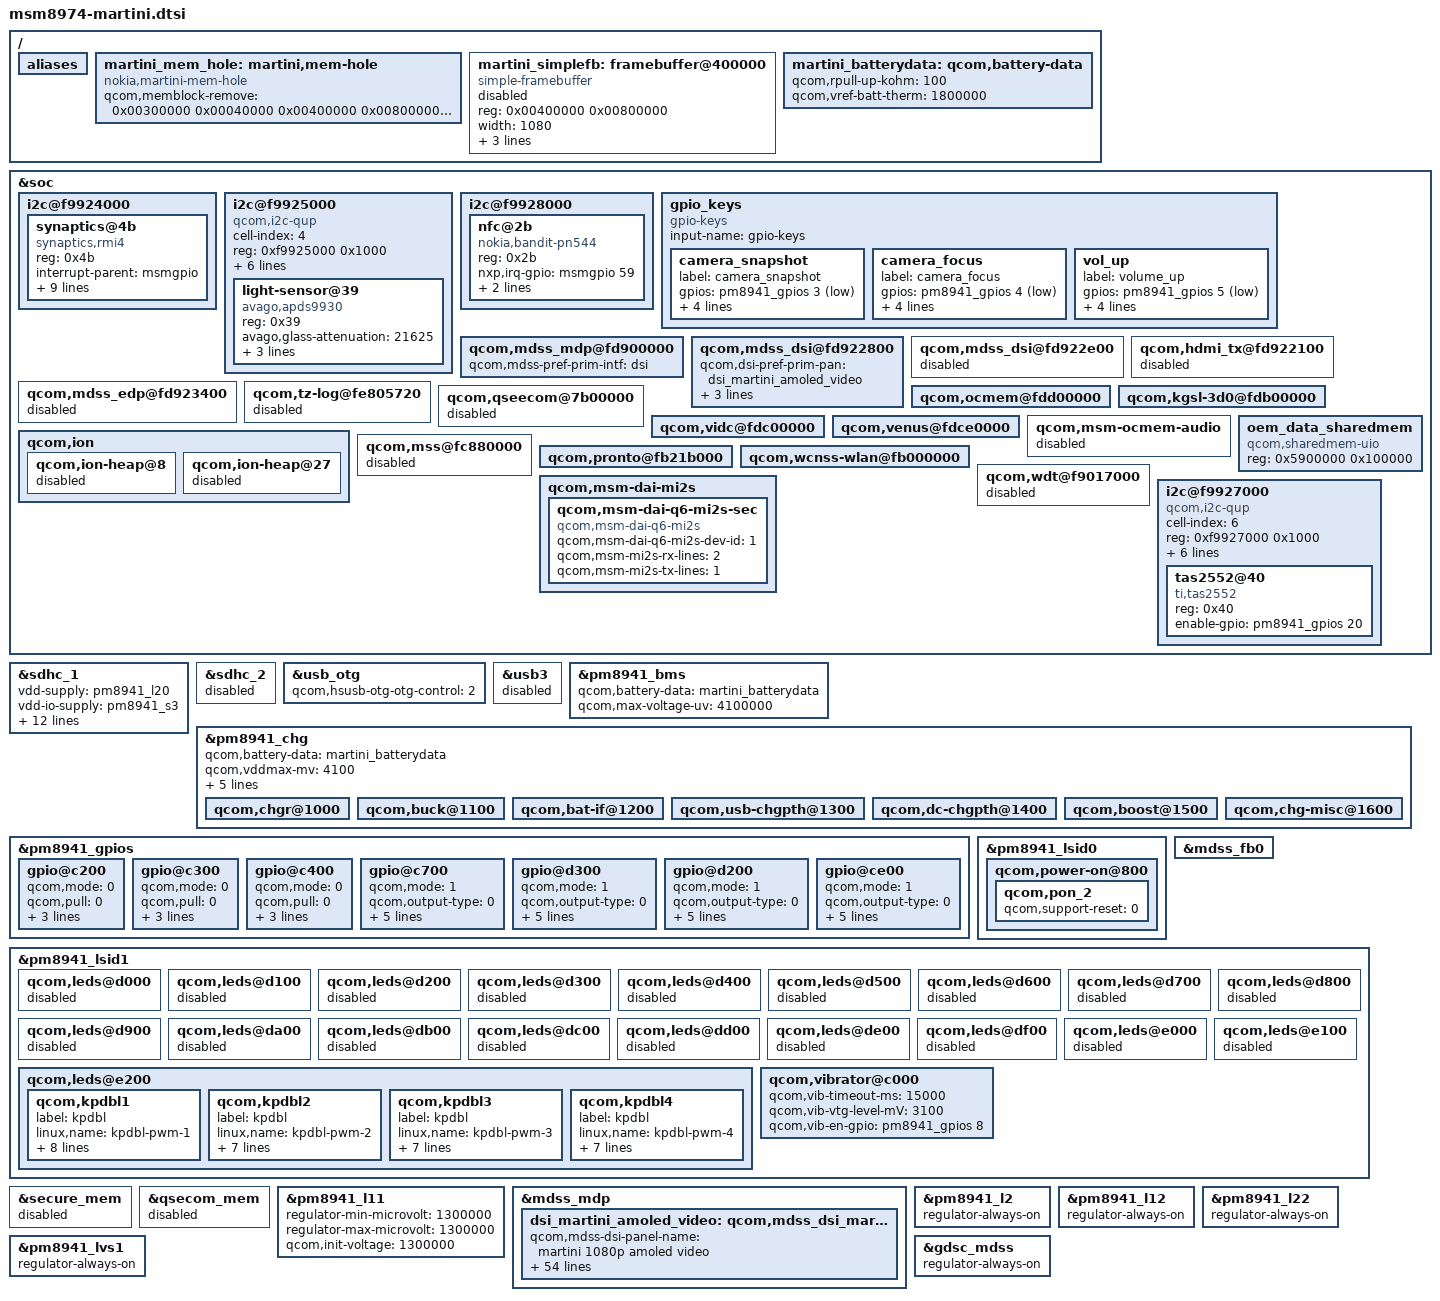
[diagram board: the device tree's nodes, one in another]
/*
 * Nokia Lumia 930 (martini), board description for the Android 3.4 kernel.
 *
 * Copyright (c) 2013, The Linux Foundation. All rights reserved.
 * Copyright (c) 2026, Lorenzo Giannoccaro.
 *
 * This program is free software; you can redistribute it and/or modify
 * it under the terms of the GNU General Public License version 2 and
 * only version 2 as published by the Free Software Foundation.
 *
 * Started from the Lumia 1520 (bandit) board, which shares the SoC, the
 * PMICs and the Windows Phone firmware. Board wiring comes from:
 *  - the stock DSDT/SSDT of the 930 as read by the mainline bring-up
 *    (Markynose, lumia930-linux): touch, light sensor, keys, UEFI parking
 *    mailboxes, framebuffer;
 *  - the LineageOS 17.1 Lumia 930 kernel (2314372037,
 *    android_kernel_nokia_martini), which boots on the phone: panel,
 *    loudspeaker amplifier, vibrator enable, WCN3680 supply, memory map,
 *    battery profile.
 * Blocks marked "copied from bandit" are SoC or firmware generic and are
 * unverified on martini. Nothing here has run on a 930 yet.
 *
 * The phone boots through the Windows Phone firmware: Nokia UEFI ->
 * bootmgr -> BootShim -> lk1st. Its TrustZone does not implement several
 * SCM calls used by Android kernels; see arch/arm/mach-msm/tz-restricted.c.
 */

/ {
	aliases {
		/* No user-accessible UART on the 930 */
	};

	/*
	 * The kernel runs with PHYS_OFFSET 0x10000000 (lk1st loads it at
	 * 0x10008000), so RAM below 256 MB is not used. Listed anyway, so that
	 * they stay out of the memory map if PHYS_OFFSET changes:
	 *  - 0x00300000 + 256 KB: UEFI MpPark code and the CPU parking
	 *    mailboxes (uefiplatWPBlue.cfg, used by platsmp.c);
	 *  - 0x00400000 + 8 MB: the framebuffer the UEFI leaves scanned out;
	 *  - 0x07b00000 + 132 MB: subsystem carve-outs, SMEM and TZ, as the
	 *    LineageOS 17.1 Lumia 930 kernel removes them.
	 */
	martini_mem_hole: martini,mem-hole {
		compatible = "nokia,martini-mem-hole";
		qcom,memblock-remove = <0x00300000 0x00040000
					0x00400000 0x00800000
					0x07b00000 0x08400000>;
	};

	/*
	 * Display: the UEFI leaves the video mode panel streamed by the MDP
	 * from 0x00400000 (1080x1920, 32 bpp; address and size as on the
	 * 1520, the 930 stock UEFI configuration gives 0x00400000-0x00c00000).
	 * MDSS takes it over (continuous splash, see the DSI and panel nodes
	 * below), so this simple-framebuffer view of the same buffer is off.
	 * The fallback device tree msm8974-v2.2-martini-simplefb.dts turns it
	 * back on with MDSS off: there RGB0 is switched to R,G,B,A by
	 * bandit-splash.c only if it finds the exact state the 1520 UEFI
	 * leaves; otherwise red and blue are swapped (cosmetic).
	 */
	martini_simplefb: framebuffer@400000 {
		compatible = "simple-framebuffer";
		status = "disabled";
		reg = <0x00400000 0x00800000>;
		width = <1080>;
		height = <1920>;
		stride = <4320>;
		format = "a8b8g8r8";	/* RGB0 set to R,G,B,A by bandit-splash.c */
	};
};

&soc {
	/*
	 * Touchscreen: Synaptics RMI4, from the stock DSDT (NOKIA_TOUCH):
	 * BLSP1 QUP2 at 0x4b, interrupt TLMM 61 (falling, needs the pull-up
	 * set by the board file), enable TLMM 60. Same wiring as the 1520.
	 * Stock PEP (\_SB.TSC1 D0): L22 at 3.0 V, 2 ms, enable TLMM 60 high,
	 * 60 ms; no I/O rail is listed. L6 (1.8 V, I2C pull-up) is kept as on
	 * the 1520 and in the mainline port, where touch works on the 930.
	 */
	i2c@f9924000 {
		synaptics@4b {
			compatible = "synaptics,rmi4";
			reg = <0x4b>;
			interrupt-parent = <&msmgpio>;
			interrupts = <61 0x2008>;
			vdd-supply = <&pm8941_l22>;
			vcc_i2c-supply = <&pm8941_l6>;
			synaptics,reset-gpio = <&msmgpio 60 0x00>;
			synaptics,irq-gpio = <&msmgpio 61 0x2008>;
			/*
			 * No display-coords: this driver reports raw sensor
			 * coordinates, so the axes use the sensor range read
			 * from F11/F12 (Android scales it to the panel).
			 */
			synaptics,i2c-pull-up;
			/*
			 * Capacitive keys below the panel (F1A 0D buttons):
			 * the Windows touch settings of the 930
			 * (martini_SynapticsTouch.inf) list Back, Start and
			 * Search on their own receive electrodes
			 * (RxElectrodeMaskButtons 0x38000000), with the same
			 * button order (FF BackButton 1, StartButton 0,
			 * SearchButton 2) as the 1520 registry, where F1A
			 * buttons 0-2 are back, start, search on the phone.
			 * Mapped as on bandit: the driver keeps 8-bit codes,
			 * so search is KEY_MENU, made app switch by the key
			 * layout; 0dbutton turns the keys off for the
			 * navigation bar.
			 * The same settings enable the wakeup gesture
			 * (WakeupGestureSupported, EnableWakeupGesture), so the
			 * wake_gesture switch (double tap to wake) applies.
			 */
			synaptics,button-map = <158 172 139>;
			/*
			 * Double tap timing of the Windows touch settings
			 * (DoubleTapMaxTapTime10ms 0x23, DoubleTapMaxTapDistance
			 * 100um 0x1e), written to F12 ctrl18 at screen off. The
			 * 5 x 5 mm dead zone has no known register.
			 */
			synaptics,dtap-max-time = <35>;
			synaptics,dtap-max-dist = <30>;
		};
	};

	/*
	 * BLSP1 QUP3: ambient light/proximity APDS-9930 at 0x39 (stock SSDT
	 * \_SB.APS1, QPDS_APS, 400 kHz); its interrupt is TLMM 74 (edge,
	 * active low, pull-up), polled by the driver for now. Stock PEP: L18
	 * at 2.85 V and LVS3 (1.8 V), both left on by the firmware, which
	 * nothing here turns off (no full regulator constraints on firmware
	 * boots).
	 * Accelerometer, gyroscope and magnetometer: none on an application
	 * processor bus. The only motion sensor device is \_SB.SEN1
	 * (QCOM2495, SSDT), which depends on the ADSP and IPC0 and only gives
	 * the mounting matrices (AROT, GROT, MROT) and the Nokia step counter,
	 * gesture and activity algorithms: the chips are driven by the
	 * Qualcomm Sensor Core on the ADSP, as on the Nexus 5. The sensors of
	 * the 1520 (BLSP2 QUP6) are not present.
	 */
	i2c@f9925000 { /* BLSP1 QUP3 */
		cell-index = <4>;
		compatible = "qcom,i2c-qup";
		reg = <0xf9925000 0x1000>;
		#address-cells = <1>;
		#size-cells = <0>;
		reg-names = "qup_phys_addr";
		interrupts = <0 97 0>;
		interrupt-names = "qup_err_intr";
		qcom,i2c-bus-freq = <100000>;
		qcom,i2c-src-freq = <19200000>;
		qcom,master-id = <86>;
		qcom,scl-gpio = <&msmgpio 11 0>;
		qcom,sda-gpio = <&msmgpio 10 0>;

		light-sensor@39 {
			compatible = "avago,apds9930";
			reg = <0x39>;
			/*
			 * Starting point only, to recheck against a lux meter.
			 * The stock driver settings (AlsPrxAlphamon, the same
			 * on the 930 registry and in the shared NMO package)
			 * give CoeffGA 0x1ba68, B 0x4ada, C 0x53c, D 0x810 on
			 * the 930 and 0x41b90, 0x45fc, 0x52b, 0x7f3 on the
			 * 1520, on top of a per-phone DPP calibration not read
			 * here. The bandit values (GA 51.4, measured; B, C, D
			 * from the datasheet) are scaled by the 930/1520 ratio
			 * of each Windows coefficient: GA x0.4207, B x1.0696,
			 * C x1.0129, D x1.0143.
			 * Proximity keeps the bandit thresholds: the stock
			 * static ones are the same on both phones (FarToNear
			 * 700, NearToFar 600, TargetCrosstalk 100) and this
			 * driver uses its own pulse count.
			 */
			avago,glass-attenuation = <21625>;
			avago,lux-coeff-b = <1992>;
			avago,lux-coeff-c = <756>;
			avago,lux-coeff-d = <1309>;
		};
	};

	/*
	 * NFC: stock SSDT \_SB.NFC1 (NXP_NFCC) is the same as on the 1520:
	 * I2C6 (BLSP1 QUP6, f9928000) at 0x2b, 400 kHz; interrupt TLMM 59
	 * (edge, active high, pull-down); outputs TLMM 57 (VEN) and TLMM 85
	 * (firmware download). Stock PEP: S3 (1.8 V) and the BBCLK2 clock
	 * buffer (ref_clk of 3-002b in clock-8974.c). The Windows NFC package
	 * carries the PN544 C3 firmware (NxpPN544c3Fw.dll), so the chip is a
	 * PN544 driven by the same character device as on bandit.
	 */
	i2c@f9928000 { /* BLSP1 QUP6 */
		nfc@2b {
			compatible = "nokia,bandit-pn544";
			reg = <0x2b>;
			nxp,irq-gpio = <&msmgpio 59 0>;
			nxp,ven-gpio = <&msmgpio 57 0>;
			nxp,firm-gpio = <&msmgpio 85 0>;
		};
	};

	/*
	 * Keys (stock DSDT): camera snapshot PM8941 GPIO 3, camera focus GPIO 4,
	 * volume up GPIO 5, all active low with pull-up; volume down is RESIN,
	 * power is PON. Same as the 1520.
	 */
	gpio_keys {
		compatible = "gpio-keys";
		input-name = "gpio-keys";

		camera_snapshot {
			label = "camera_snapshot";
			gpios = <&pm8941_gpios 3 0x1>;
			linux,input-type = <1>;
			linux,code = <0x2fe>;
			gpio-key,wakeup;
			debounce-interval = <15>;
		};

		camera_focus {
			label = "camera_focus";
			gpios = <&pm8941_gpios 4 0x1>;
			linux,input-type = <1>;
			linux,code = <0x210>;
			gpio-key,wakeup;
			debounce-interval = <15>;
		};

		vol_up {
			label = "volume_up";
			gpios = <&pm8941_gpios 5 0x1>;
			linux,input-type = <1>;
			linux,code = <115>;
			gpio-key,wakeup;
			debounce-interval = <15>;
		};
	};

	/*
	 * Display: MDSS takes over the video mode panel the UEFI leaves
	 * streaming (continuous splash), as on the 1520 with its command mode
	 * panel:
	 *  - the DSI PHY and PLL stay as the UEFI set them
	 *    (nokia,keep-firmware-phy: never reprogrammed, clamped or reset,
	 *    link clock rates never set; the PLL relocks at the rate the UEFI
	 *    left after a screen off);
	 *  - the interface timing and the DSI video mode setup are read back
	 *    from the running hardware (nokia,keep-firmware-timing in the
	 *    panel node), so the handoff rewrites the same values and later
	 *    power ons program what the panel was initialised with;
	 *  - the first unblank sends no panel command; the MDP switches the
	 *    pipe left by the UEFI to border fill for one frame before it
	 *    attaches its IOMMU, then shows Android;
	 *  - screen off: display off + sleep in (DCS 28, 10), reset low;
	 *    screen on: reset sequence, full panel init (DCS), as the 17.1
	 *    Lumia 930 kernel; LVS1 and the DSI rails stay on (see below).
	 * Reset on PM8941 GPIO 19 (base DSI node, configured below); no MTP
	 * enable or TE lines (the stock panel has no TE in video mode).
	 * Fallback without MDSS: msm8974-v2.2-martini-simplefb.dts.
	 */
	qcom,mdss_mdp@fd900000 {
		qcom,mdss-pref-prim-intf = "dsi";
	};
	qcom,mdss_dsi@fd922800 {
		qcom,dsi-pref-prim-pan = <&dsi_martini_amoled_video>;
		/delete-property/ qcom,platform-enable-gpio;
		/delete-property/ qcom,platform-te-gpio;
		qcom,platform-regulator-settings = [07 09 03 00 20 00 01];
		nokia,keep-firmware-phy;
	};
	qcom,mdss_dsi@fd922e00 {
		status = "disabled";
	};
	qcom,hdmi_tx@fd922100 {
		status = "disabled";
	};
	qcom,mdss_edp@fd923400 {
		status = "disabled";
	};

	/*
	 * Copied from bandit, unverified on martini: keep off what needs
	 * TrustZone services the Windows Phone firmware does not provide
	 * (TZ log, QSEECOM); OCMEM, Adreno 330 (no TZ DCVS) and Venus (PAS)
	 * work on the 1520 with the same firmware family.
	 */
	qcom,tz-log@fe805720 {
		status = "disabled";
	};
	qcom,qseecom@7b00000 {
		status = "disabled";
	};
	qcom,ocmem@fdd00000 {
		status = "ok";	/* Adreno 330 GMEM */
	};
	qcom,kgsl-3d0@fdb00000 {
		status = "ok";
	};
	qcom,vidc@fdc00000 {
		status = "ok";
	};
	qcom,venus@fdce0000 {
		status = "ok";	/* PAS proc 9: the TZ authenticates it */
	};
};

/* eMMC, copied from bandit (8-bit bus, as the 17.1 Lumia 930 kernel uses) */
&sdhc_1 {
	vdd-supply = <&pm8941_l20>;
	vdd-io-supply = <&pm8941_s3>;

	qcom,vdd-always-on;
	qcom,vdd-lpm-sup;
	qcom,vdd-voltage-level = <2950000 2950000>;
	qcom,vdd-current-level = <800 500000>;

	qcom,vdd-io-always-on;
	qcom,vdd-io-voltage-level = <1800000 1800000>;
	qcom,vdd-io-current-level = <250 154000>;

	qcom,pad-pull-on = <0x0 0x3 0x3>;
	qcom,pad-pull-off = <0x0 0x3 0x3>;
	qcom,pad-drv-on = <0x7 0x4 0x4>;
	qcom,pad-drv-off = <0x0 0x0 0x0>;

	qcom,nonremovable;
	status = "ok";
};

/* No microSD slot on the 930 */
&sdhc_2 {
	status = "disabled";
};

/*
 * Copied from bandit, unverified on martini: the micro-USB port on the
 * USB 2.0 controller at f9a55000 (the mainline 930 port drives it as
 * ci_hdrc), VBUS detection through the PM8941 charger.
 */
&usb_otg {
	status = "ok";
	qcom,hsusb-otg-otg-control = <2>;
};

&usb3 {
	status = "disabled";
};

/ {
	martini_batterydata: qcom,battery-data {
		qcom,rpull-up-kohm = <100>;
		qcom,vref-batt-therm = <1800000>;

		/include/ "batterydata-nokia-bv5qw.dtsi"
	};
};

/*
 * BV-5QW, 2420 mAh (the Nokia profile; the mainline notes say 2500 mAh).
 * Without the BIF authentication Windows does, use the default table of
 * the stock battery.json, as the mainline port does: charge to 4.10 V at
 * 900 mA, minimum input 4.30 V, recharge below 4.00 V (vbatdet delta).
 * VDD_SAFE is write-once on the PM8941 and left by the UEFI, so it is not
 * set here. Safety timer raised for 2420 mAh at 900 mA.
 * Qi wireless charging (stock SSDT \_SB.NEDD, NOKI0B00, the Nokia energy
 * driver): interrupts DCIN_VALID, BATT_PRES, WC_DET and CHG_GONE; outputs
 * WC_EN = PM8941 GPIO 7, WC_DET = GPIO 6 (input, pull-up, wake),
 * WC_PMA = GPIO 22. The receiver feeds the PM8941 DC input; GPIO 6, 7 and
 * 22 are left as the UEFI set them.
 * TODO(martini): read BATTERY.PROVISION / battery.json on the phone before
 * raising the limits towards 4.35 V; describe WC_EN/WC_DET if the DC path
 * does not charge on its own.
 */
&pm8941_bms {
	status = "ok";
	qcom,battery-data = <&martini_batterydata>;
	qcom,max-voltage-uv = <4100000>;
};

&pm8941_chg {
	status = "ok";
	qcom,battery-data = <&martini_batterydata>;
	qcom,vddmax-mv = <4100>;
	qcom,vinmin-mv = <4300>;
	qcom,ibatmax-ma = <900>;
	qcom,ibatsafe-ma = <900>;
	qcom,vbatdet-delta-mv = <100>;
	qcom,tchg-mins = <240>;

	qcom,chgr@1000 {
		status = "ok";
	};
	qcom,buck@1100 {
		status = "ok";
	};
	qcom,bat-if@1200 {
		status = "ok";
	};
	qcom,usb-chgpth@1300 {
		status = "ok";
	};
	qcom,dc-chgpth@1400 {
		status = "ok";
	};
	qcom,boost@1500 {
		status = "ok";
	};
	qcom,chg-misc@1600 {
		status = "ok";
	};
};

&pm8941_gpios {
	gpio@c200 { /* GPIO 3: camera snapshot */
		qcom,mode = <0>;
		qcom,pull = <0>;
		qcom,vin-sel = <2>;
		qcom,src-sel = <0>;
		qcom,master-en = <1>;
	};

	gpio@c300 { /* GPIO 4: camera focus */
		qcom,mode = <0>;
		qcom,pull = <0>;
		qcom,vin-sel = <2>;
		qcom,src-sel = <0>;
		qcom,master-en = <1>;
	};

	gpio@c400 { /* GPIO 5: volume up */
		qcom,mode = <0>;
		qcom,pull = <0>;
		qcom,vin-sel = <2>;
		qcom,src-sel = <0>;
		qcom,master-en = <1>;
	};

	/*
	 * GPIO 8: VIBRA_AMP_EN, enable of the motor driver (17.1 Lumia 930
	 * kernel; stock DSDT \_SB.VIB1 NOKIA_VIBRA and SSDT \_SB.VIB2 ODDT_VIB:
	 * PM8941 GPIO 8, pull-down). Digital output, low until the vibrator
	 * driver raises it.
	 */
	gpio@c700 {
		qcom,mode = <1>;
		qcom,output-type = <0>;
		qcom,invert = <0>;
		qcom,vin-sel = <2>;
		qcom,out-strength = <1>;
		qcom,src-sel = <0>;
		qcom,master-en = <1>;
	};

	/*
	 * GPIO 20: IHF_EN, nSHUTDOWN of the TAS2552 (17.1 Lumia 930 kernel;
	 * stock DSDT \_SB.VISA: I2C5 at 0x40 and PM8941 GPIO 20).
	 * Low until the amplifier driver raises it.
	 */
	gpio@d300 {
		qcom,mode = <1>;
		qcom,output-type = <0>;
		qcom,invert = <0>;
		qcom,vin-sel = <2>;
		qcom,out-strength = <1>;
		qcom,src-sel = <0>;
		qcom,master-en = <1>;
	};

	/*
	 * GPIO 19: panel reset (DSI qcom,platform-reset-gpio), as the stock
	 * PEP sets it for \_SB.DISP: digital output, CMOS, VIN2 (1.8 V),
	 * strength high, high in D0 and low in D3. No qcom,invert here: the
	 * level stays the one the UEFI left (high, panel running) until the
	 * DSI driver drives it at the first screen off. The 17.1 Lumia 930
	 * kernel sets the same, with strength low.
	 */
	gpio@d200 {
		qcom,mode = <1>;		/* digital output */
		qcom,output-type = <0>;		/* CMOS */
		qcom,pull = <5>;		/* no pull */
		qcom,vin-sel = <2>;		/* VIN2, 1.8 V */
		qcom,out-strength = <3>;	/* high, as the stock PEP */
		qcom,src-sel = <0>;		/* constant */
		qcom,master-en = <1>;
	};
};

/* Volume down (RESIN): key only, no PMIC reset on a long press */
&pm8941_lsid0 {
	qcom,power-on@800 {
		qcom,pon_2 {
			qcom,support-reset = <0>;
		};
	};
};

/*
 * The MTP/OnePlus splash carve-out (0x03200000) lies below PHYS_OFFSET
 * and is not the UEFI framebuffer: reserving it makes bootmem BUG() in
 * paging_init (seen on the 1520).
 */
&mdss_fb0 {
	/delete-property/ qcom,memblock-reserve;
};

/*
 * LEDs: msm-pm8941.dtsi declares the qcom,leds-qpnp peripherals without
 * child nodes, so every probe fails with -ECHILD. The 930 panel is AMOLED
 * (brightness through DCS, no WLED).
 * No notification LED (no RGB1 device in the stock DSDT/SSDT). The camera
 * flash is \_SB.CAMS.FLSH (QCOM0705, DSDT): an external driver on TLMM 83
 * and 84, as on the 1520, not a PM8941 flash block; left off with the
 * camera.
 * All PM8941 LED blocks but KPDBL (below) are off.
 */
&pm8941_lsid1 {
	qcom,leds@d000 {
		status = "disabled";
	};
	qcom,leds@d100 {
		status = "disabled";
	};
	qcom,leds@d200 {
		status = "disabled";
	};
	qcom,leds@d300 {
		status = "disabled";
	};
	qcom,leds@d400 {
		status = "disabled";
	};
	qcom,leds@d500 {
		status = "disabled";
	};
	qcom,leds@d600 {
		status = "disabled";
	};
	qcom,leds@d700 {
		status = "disabled";
	};
	qcom,leds@d800 {
		status = "disabled";
	};
	qcom,leds@d900 {
		status = "disabled";
	};
	qcom,leds@da00 {
		status = "disabled";
	};
	qcom,leds@db00 {
		status = "disabled";
	};
	qcom,leds@dc00 {
		status = "disabled";
	};
	qcom,leds@dd00 {
		status = "disabled";
	};
	qcom,leds@de00 {
		status = "disabled";
	};
	qcom,leds@df00 {
		status = "disabled";
	};
	qcom,leds@e000 {
		status = "disabled";
	};
	qcom,leds@e100 {
		status = "disabled";
	};
	/*
	 * Capacitive key backlight: the PM8941 keypad backlight (KPDBL) rows,
	 * as on the 1520 (bandit 23b5274d, seen working there). Evidence on
	 * the 930:
	 *  - stock DSDT \_SB.HWN0 (QCOM0D50, the Qualcomm HWN LED driver used
	 *    by the panel driver's key light code) owns the same PM8941 SID 1
	 *    peripherals as on the 1520, 0xd0, 0xe2 (KPDBL) and 0xe3 (_CRS),
	 *    and its HWNL/CFG0 package matches the 1520 one except one byte
	 *    (element 12: 0x02 here, 0x07 on the 1520), probably the mask of
	 *    the rows in use;
	 *  - stock registry (NOKIA_PANEL\Parameters\Settings): Back, Win and
	 *    Search LEDs in groups 0x3 as on the 1520, LIGHT_LedGroup3_Pct
	 *    0x32 (0x64 on the 1520); touch settings: three button LEDs, on
	 *    below 100 lux.
	 * All four rows are registered and driven together by the lights HAL,
	 * as on bandit; rows with no LED just sink nothing.
	 * TODO(martini): check on the phone which row lights the keys.
	 */
	qcom,leds@e200 {
		status = "okay";

		qcom,kpdbl1 {
			label = "kpdbl";
			linux,name = "kpdbl-pwm-1";
			qcom,mode = "pwm";
			qcom,pwm-channel = <8>;
			qcom,pwm-us = <1000>;
			qcom,id = <7>;
			qcom,max-current = <20>;
			qcom,row-id = <0>;
			qcom,row-src-en;
			qcom,always-on;
		};

		qcom,kpdbl2 {
			label = "kpdbl";
			linux,name = "kpdbl-pwm-2";
			qcom,mode = "pwm";
			qcom,pwm-channel = <9>;
			qcom,pwm-us = <1000>;
			qcom,id = <7>;
			qcom,max-current = <20>;
			qcom,row-id = <1>;
			qcom,row-src-en;
		};

		qcom,kpdbl3 {
			label = "kpdbl";
			linux,name = "kpdbl-pwm-3";
			qcom,mode = "pwm";
			qcom,pwm-channel = <10>;
			qcom,pwm-us = <1000>;
			qcom,id = <7>;
			qcom,max-current = <20>;
			qcom,row-id = <2>;
			qcom,row-src-en;
		};

		qcom,kpdbl4 {
			label = "kpdbl";
			linux,name = "kpdbl-pwm-4";
			qcom,mode = "pwm";
			qcom,pwm-channel = <11>;
			qcom,pwm-us = <1000>;
			qcom,id = <7>;
			qcom,max-current = <20>;
			qcom,row-id = <3>;
			qcom,row-src-en;
		};
	};
};

/* Copied from bandit: OCMEM audio client would defer forever */
&soc {
	qcom,msm-ocmem-audio {
		status = "disabled";
	};
};

/*
 * Copied from bandit (firmware generic): the Windows Phone TrustZone runs
 * no Android QSEE apps, so the secure (CP_MM) and QSEECOM heaps are
 * dropped with their CMA regions.
 */
&secure_mem {
	status = "disabled";
};

&qsecom_mem {
	status = "disabled";
};

&soc {
	qcom,ion {
		qcom,ion-heap@8 {
			status = "disabled";
		};
		qcom,ion-heap@27 {
			status = "disabled";
		};
	};
};

/*
 * Copied from bandit: the "oem_data" shared memory UIO that the msm8974
 * rmt_storage blob requires, below PHYS_OFFSET and clear of the PIL region.
 */
&soc {
	oem_data_sharedmem {
		compatible = "qcom,sharedmem-uio";
		reg = <0x5900000 0x100000>;
		reg-names = "oem_data";
	};
};

/*
 * Modem off for the first boot, as in the 17.1 Lumia 930 kernel. The PIL
 * here can load the SSD-encrypted Nokia images (pil-ssd.c, working on the
 * 1520), but a failed start can reset the phone.
 * TODO(martini): enable qcom,mss@fc880000 once the phone boots and the
 * modem images on the 930 are checked (SSD header, MBA).
 *
 * WCNSS (Pronto + WCN3680, Wi-Fi/Bluetooth) on, with the 5-wire link
 * muxed by the board file: Wi-Fi works in the 17.1 Lumia 930 kernel
 * (Bluetooth was left off there).
 */
&soc {
	qcom,mss@fc880000 {
		status = "disabled";
	};
	qcom,pronto@fb21b000 {
		status = "ok";
	};
	qcom,wcnss-wlan@fb000000 {
		status = "ok";
	};
};

/* WCN3680 RF supply at 1.3 V, as the 17.1 Lumia 930 kernel sets it */
&pm8941_l11 {
	regulator-min-microvolt = <1300000>;
	regulator-max-microvolt = <1300000>;
	qcom,init-voltage = <1300000>;
};

/*
 * Vibration motor on the PM8941 (as on the 1520), behind an external
 * driver enabled by PM8941 GPIO 8 (VIBRA_AMP_EN, 17.1 Lumia 930 kernel).
 */
&pm8941_lsid1 {
	qcom,vibrator@c000 {
		status = "okay";
		qcom,vib-timeout-ms = <15000>;
		qcom,vib-vtg-level-mV = <3100>;
		qcom,vib-en-gpio = <&pm8941_gpios 8 0>;
	};
};

/*
 * Copied from bandit: APSS watchdog off, the Windows Phone firmware does
 * not let Linux program it (boot loop on the 1520).
 */
&soc {
	qcom,wdt@f9017000 {
		status = "disabled";
	};
};

/*
 * Panel "Aurora": 5" 1080x1920 AMOLED, DSI video mode, 4 lanes, 60 Hz,
 * brightness through DCS (0x51), reset on PM8941 GPIO 19 (base DSI node).
 * Timings, lanes, PHY and command sequences from the 17.1 Lumia 930 kernel
 * (dsi-panel-martini-amoled-dsi0-video.dtsi, the same values as the
 * Android4Lumia dsi-panel-aurora-1080p-video.dtsi), converted to the
 * bindings of this kernel. Stock data of the 930:
 *  - the panel XML of the stock DSDT (\_SB.GPU0._ROM, "Aurora", the
 *    panel configuration of the Windows display driver): 1080x1920,
 *    24 bpp, 4 lanes, 60 Hz, LP in BLLP and BLLP EOF, EoT not appended,
 *    PHY in DCDC mode; porches h 16/10/26, v 0/0/2 (front/back/pulse),
 *    the same template numbers as the 1520 command mode XML, while the
 *    17.1 kernel drives the panel with h 46/30/20, v 13/2/1. Which ones
 *    the UEFI uses is not known without the phone: the timing below is
 *    only a fallback, nokia,keep-firmware-timing takes the one of the
 *    running interface at boot and logs both;
 *  - the init sequence of that XML (commented out, like the 1520 one:
 *    Windows uses the panel as the UEFI leaves it) is the 17.1 one byte
 *    for byte (11, F0 5A 5A, CB, F7 03, F0 A5 A5, 53 2C, 51, 29), with
 *    21 ms after sleep out (120 ms here, as the 17.1 kernel) and 51 80
 *    instead of 51 ff; reset "DSI_PANEL_RESET, 0, 10" (active low);
 *  - physical size 62.00 x 115.00 mm, from the touch settings
 *    (DisplayWidth10um 0x1838, DisplayHeight10um 0x2cec; the XML EDID
 *    gives 62 x 110 mm); the 17.1 kernel had 65 mm for the width;
 *  - DCS brightness 0..255: oempanel.sys logs "Brightness: %u/255" and
 *    its on sequence ends with 51 ff; the 17.1 kernel capped the level
 *    at 128, the XML init value;
 *  - Samsung panel (oempanel.sys string), consistent with the Samsung
 *    level 2 key F0 5A 5A of the init sequence.
 * The PHY is kept as programmed by the UEFI (nokia,keep-firmware-phy):
 * the PHY timings below are not written. With nokia,keep-firmware-timing
 * the DSI video mode setup (traffic mode, LP states, lanes, t-clk, EoT,
 * RGB order) is also taken from the controller the UEFI left running.
 */
&mdss_mdp {
	dsi_martini_amoled_video: qcom,mdss_dsi_martini_amoled_video {
		qcom,mdss-dsi-panel-name = "martini 1080p amoled video";
		qcom,mdss-dsi-panel-controller = <&mdss_dsi0>;
		qcom,mdss-dsi-panel-type = "dsi_video_mode";
		qcom,mdss-dsi-panel-destination = "display_1";
		qcom,cont-splash-enabled;
		/* timing and DSI video setup from the running UEFI */
		nokia,keep-firmware-timing;
		qcom,mdss-dsi-panel-framerate = <60>;
		qcom,mdss-dsi-virtual-channel-id = <0>;
		qcom,mdss-dsi-stream = <0>;
		qcom,mdss-dsi-panel-width = <1080>;
		qcom,mdss-dsi-panel-height = <1920>;
		qcom,mdss-pan-physical-width-dimension = <62>;
		qcom,mdss-pan-physical-height-dimension = <115>;
		qcom,mdss-dsi-h-back-porch = <30>;
		qcom,mdss-dsi-h-pulse-width = <20>;
		qcom,mdss-dsi-h-front-porch = <46>;
		qcom,mdss-dsi-h-sync-skew = <0>;
		qcom,mdss-dsi-v-back-porch = <2>;
		qcom,mdss-dsi-v-pulse-width = <1>;
		qcom,mdss-dsi-v-front-porch = <13>;
		qcom,mdss-dsi-h-left-border = <0>;
		qcom,mdss-dsi-h-right-border = <0>;
		qcom,mdss-dsi-v-top-border = <0>;
		qcom,mdss-dsi-v-bottom-border = <0>;
		qcom,mdss-dsi-bpp = <24>;
		qcom,mdss-dsi-color-order = "rgb_swap_rgb";
		qcom,mdss-dsi-underflow-color = <0xff>;
		qcom,mdss-dsi-border-color = <0>;
		qcom,mdss-dsi-h-sync-pulse = <1>;
		qcom,mdss-dsi-traffic-mode = "burst_mode";
		qcom,mdss-dsi-bllp-power-mode;
		qcom,mdss-dsi-bllp-eof-power-mode;
		qcom,mdss-dsi-lane-0-state;
		qcom,mdss-dsi-lane-1-state;
		qcom,mdss-dsi-lane-2-state;
		qcom,mdss-dsi-lane-3-state;
		qcom,mdss-dsi-lane-map = "lane_map_0123";
		qcom,mdss-dsi-t-clk-pre = <0x36>;
		qcom,mdss-dsi-t-clk-post = <0x00>;
		qcom,mdss-dsi-panel-timings = [d5 9a 1e 00 66 5e 36 9e 55 03 04 00];
		qcom,mdss-dsi-mdp-trigger = "none";
		qcom,mdss-dsi-dma-trigger = "trigger_sw";
		qcom,mdss-dsi-reset-sequence = <1 20>, <0 200>, <1 20>;
		/*
		 * Screen on after a reset: sleep out, Samsung-style level 2
		 * key (F0 5A 5A), panel setup, key lock (F0 A5 A5), brightness
		 * control on (53 2C), full brightness (the driver then restores
		 * the Android level), display on. Screen off: display off,
		 * brightness control off, sleep in. Neither is sent at the first
		 * unblank (continuous splash).
		 */
		qcom,mdss-dsi-on-command = [05 01 00 00 78 00 02 11 00
				39 01 00 00 00 00 03 f0 5a 5a
				39 01 00 00 00 00 0e cb 16 00 01 01 de 01 00 00 03 00 06 00 08
				39 01 00 00 00 00 02 f7 03
				39 01 00 00 65 00 03 f0 a5 a5
				15 01 00 00 00 00 02 53 2c
				15 01 00 00 00 00 02 51 ff
				05 01 00 00 00 00 02 29 00];
		qcom,mdss-dsi-off-command = [05 01 00 00 00 00 02 28 00
				15 01 00 00 00 00 02 53 00
				05 01 00 00 78 00 02 10 00];
		qcom,mdss-dsi-on-command-state = "dsi_lp_mode";
		qcom,mdss-dsi-off-command-state = "dsi_hs_mode";
		qcom,mdss-dsi-bl-pmic-control-type = "bl_ctrl_dcs";
		/* DCS 0x51 range 1..255 (Windows panel driver) */
		qcom,mdss-dsi-bl-min-level = <1>;
		qcom,mdss-dsi-bl-max-level = <255>;
	};
};

/*
 * Panel and DSI rails, MDSS GDSC never cut. Stock PEP: the MDP
 * (\_SB.GPU0) uses L2 (1.2 V) and L12 (1.8 V); the panel (\_SB.DISP) uses
 * LVS1 (1.8 V), then 25 ms, then PM8941 GPIO 19 (reset) as a high output
 * (VIN2), and the reverse at power off (reset low, 10 ms, LVS1 off).
 * There is no AMOLED ELVDD/ELVSS rail on the SoC side: the panel module
 * makes them. L22 (3.0 V) is the touch rail (\_SB.TSC1), kept on for the
 * wakeup gesture.
 * With MDSS, the DSI node votes for vdda (L2), vdd (L22) and vddio (L12),
 * as the 17.1 Lumia 930 kernel; all of them, LVS1 and the GDSC stay on
 * when the screen is off: the PHY and PLL kept from the UEFI live in the
 * GDSC, and LVS1 is not switched by the 17.1 kernel either. Screen off is
 * sleep in plus reset low; the PEP's LVS1 cut is not done.
 * \_SB.DISP also lists TLMM 12 (MDP_VSYNC, the panel TE) and TLMM 32, 33
 * and 34 (roles unknown, not touched).
 */
&pm8941_l2 {
	regulator-always-on;
};
&pm8941_l12 {
	regulator-always-on;
};
&pm8941_l22 {
	regulator-always-on;
};
&pm8941_lvs1 {
	regulator-always-on;
};
&gdsc_mdss {
	regulator-always-on;
};

/*
 * Audio: WCD9320 (Taiko) codec on SLIMbus, as on the 1520 and in the 17.1
 * Lumia 930 kernel (msm8974-taiko-mtp-snd-card). PM8941 GPIO 15 is the
 * codec MCLK (DIV_CLK1, special function 1), as both kernels set it.
 * TODO(martini): headset jack switch polarity, micbias capacitors and the
 * earpiece path from the stock audio configuration.
 */
&pm8941_gpios {
	gpio@ce00 { /* GPIO 15: codec MCLK (DIV_CLK1) */
		qcom,mode = <1>;		/* digital output */
		qcom,output-type = <0>;		/* CMOS */
		qcom,pull = <5>;		/* no pull */
		qcom,vin-sel = <2>;		/* VIN2, 1.8 V */
		qcom,out-strength = <1>;	/* low, as the 17.1 kernel */
		qcom,src-sel = <2>;		/* function 1: DIV_CLK1 */
		qcom,master-en = <1>;
	};
};

/*
 * Loudspeaker: TI TAS2552 ("N2182") on BLSP1 QUP5 at 0x40, audio in on
 * the secondary MI2S SD1 (TLMM 82), nSHUTDOWN on PM8941 GPIO 20: the same
 * part, bus and lines as the 1520 (confirmed by the 17.1 Lumia 930
 * kernel). The machine driver and pin setup are shared with bandit.
 */
&soc {
	qcom,msm-dai-mi2s {
		qcom,msm-dai-q6-mi2s-sec {
			compatible = "qcom,msm-dai-q6-mi2s";
			qcom,msm-dai-q6-mi2s-dev-id = <1>;
			qcom,msm-mi2s-rx-lines = <2>;	/* SD1, TLMM 82 */
			qcom,msm-mi2s-tx-lines = <1>;	/* SD0, TLMM 81 */
		};
	};

	i2c@f9927000 { /* BLSP1 QUP5 */
		cell-index = <6>;
		compatible = "qcom,i2c-qup";
		reg = <0xf9927000 0x1000>;
		#address-cells = <1>;
		#size-cells = <0>;
		reg-names = "qup_phys_addr";
		interrupts = <0 99 0>;
		interrupt-names = "qup_err_intr";
		qcom,i2c-bus-freq = <100000>;
		qcom,i2c-src-freq = <19200000>;
		qcom,master-id = <86>;
		qcom,scl-gpio = <&msmgpio 26 0>;
		qcom,sda-gpio = <&msmgpio 25 0>;

		tas2552@40 {
			compatible = "ti,tas2552";
			reg = <0x40>;
			enable-gpio = <&pm8941_gpios 20 0>;
		};
	};
};
